# HC32M413 register map
File version: 1.0
CPU: CM4 r0p1, little endian, MPU, FPU, 4 interrupt priority bits
Registers are 32-bit, read-write, reset 0x0 unless marked. A register's access mark holds for its fields unless they carry their own. Offsets are from the block's base; [hi:lo] are bit positions; {n}, {i} and the like mark numbered series.

## ICG
Base 0x00020000
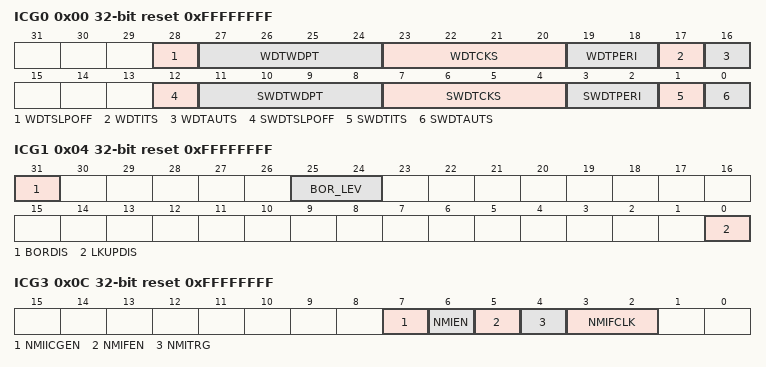
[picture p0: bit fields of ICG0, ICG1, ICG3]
0x00 ICG0 ro reset 0xFFFFFFFF
  [28] WDTSLPOFF, [27:24] WDTWDPT, [23:20] WDTCKS, [19:18] WDTPERI, [17] WDTITS, [16] WDTAUTS, [12] SWDTSLPOFF, [11:8] SWDTWDPT, [7:4] SWDTCKS, [3:2] SWDTPERI, [1] SWDTITS, [0] SWDTAUTS
0x04 ICG1 ro reset 0xFFFFFFFF
  [31] BORDIS, [25:24] BOR_LEV, [0] LKUPDIS
0x08 ICG2 ro reset 0xFFFFFFFF
  [2:0] HRCFREQSEL
0x0C ICG3 ro reset 0xFFFFFFFF
  [7] NMIICGEN, [6] NMIEN, [5] NMIFEN, [4] NMITRG, [3:2] NMIFCLK
0x10 ICG4 ro reset 0xFFFFFFFF

## INTC
Base 0x40051000
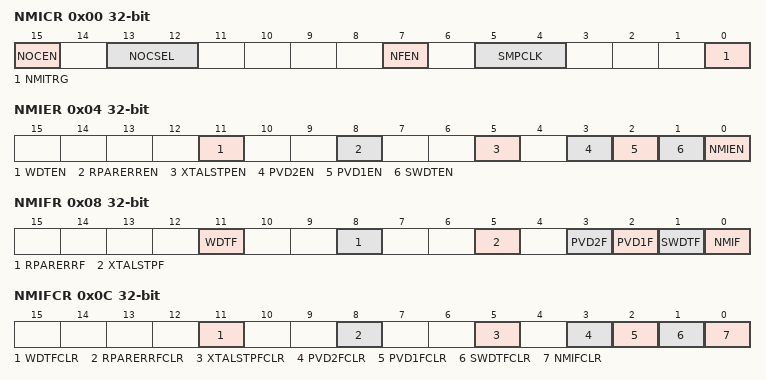
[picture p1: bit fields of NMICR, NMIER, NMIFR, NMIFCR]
0x00 NMICR
  [15] NOCEN, [13:12] NOCSEL, [7] NFEN, [5:4] SMPCLK, [0] NMITRG
0x04 NMIER
  [11] WDTEN, [8] RPARERREN, [5] XTALSTPEN, [3] PVD2EN, [2] PVD1EN, [1] SWDTEN, [0] NMIEN
0x08 NMIFR ro
  [11] WDTF, [8] RPARERRF, [5] XTALSTPF, [3] PVD2F, [2] PVD1F, [1] SWDTF, [0] NMIF
0x0C NMIFCR wo
  [11] WDTFCLR, [8] RPARERRFCLR, [5] XTALSTPFCLR, [3] PVD2FCLR, [2] PVD1FCLR, [1] SWDTFCLR, [0] NMIFCLR
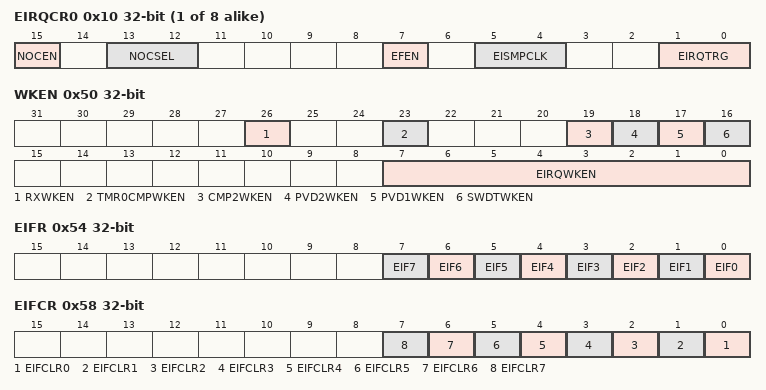
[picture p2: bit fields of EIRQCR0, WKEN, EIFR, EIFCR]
{0x10+4i} EIRQCR{i} (i=0..7)
  [15] NOCEN, [13:12] NOCSEL, [7] EFEN, [5:4] EISMPCLK, [1:0] EIRQTRG
0x50 WKEN
  [26] RXWKEN, [23] TMR0CMPWKEN, [19] CMP2WKEN, [18] PVD2WKEN, [17] PVD1WKEN, [16] SWDTWKEN, [7:0] EIRQWKEN
0x54 EIFR
  [n] EIF{n} (n=0..7)
0x58 EIFCR
  [n] EIFCLR{n} (n=0..7)
{0x5C+4i} INTSEL{i} reset 0x1FF (i=0..15)
  [8:0] INTSEL
{0x25C+4i} INTEN{i} reset 0xFFFFFFFF (i=0..15)
  [31:0] INTEN
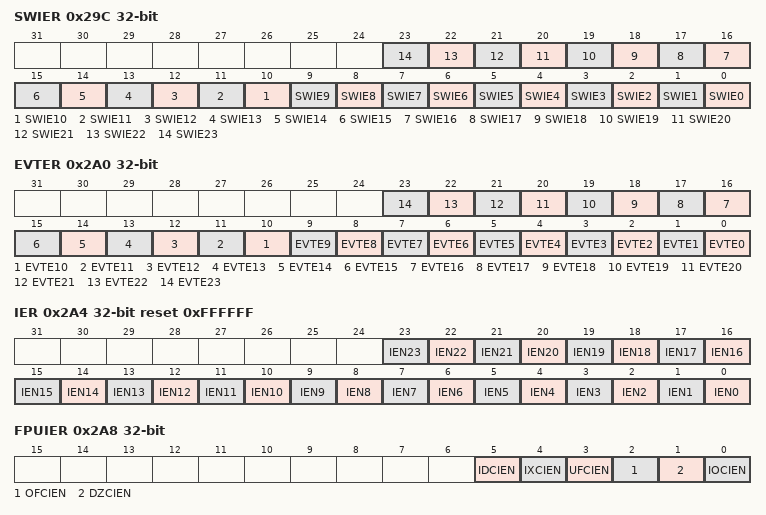
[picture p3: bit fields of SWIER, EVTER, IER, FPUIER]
0x29C SWIER
  [n] SWIE{n} (n=0..23)
0x2A0 EVTER
  [n] EVTE{n} (n=0..23)
0x2A4 IER reset 0xFFFFFF
  [n] IEN{n} (n=0..23)
0x2A8 FPUIER
  [5] IDCIEN, [4] IXCIEN, [3] UFCIEN, [2] OFCIEN, [1] DZCIEN, [0] IOCIEN

## MAU
Base 0x40054800
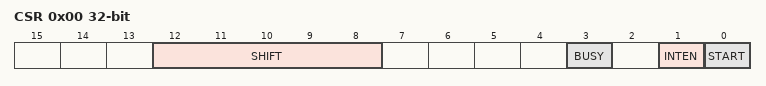
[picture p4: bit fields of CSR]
0x00 CSR
  [12:8] SHIFT, [3] BUSY, [1] INTEN, [0] START
0x04 DTR0
  [31:0] SQRT_DIN
0x0C RTR0
  [31:0] SQRT_DOUT
0x1C DTR1
  [11:0] SIN_DIN
0x20 RTR1
  [15:0] SIN_DOUT
0x24 ATAN_DIN
  [11:0] ATAN_DIN
0x28 ATAN_DOUT
  [15:0] ATAN_DOUT

## PERIC
Base 0x40054C00
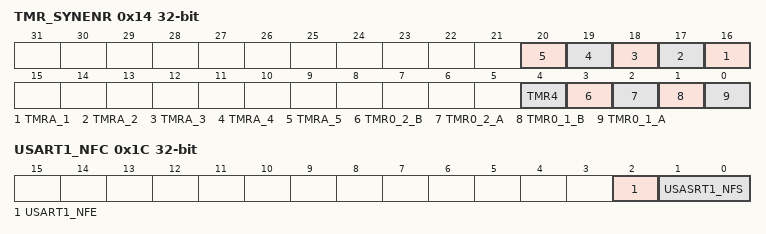
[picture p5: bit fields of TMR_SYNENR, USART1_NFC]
0x14 TMR_SYNENR
  [n+15] TMRA_{n} (n=1..5), [4] TMR4, [3] TMR0_2_B, [2] TMR0_2_A, [1] TMR0_1_B, [0] TMR0_1_A
0x1C USART1_NFC
  [2] USART1_NFE, [1:0] USASRT1_NFS

## PWC
Base 0x40054000
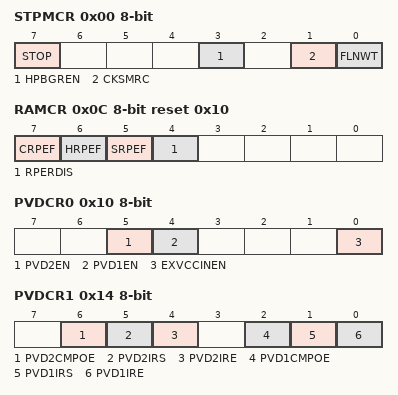
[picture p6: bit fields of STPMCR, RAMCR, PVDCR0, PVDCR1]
0x00 STPMCR 8-bit
  [7] STOP, [3] HPBGREN, [1] CKSMRC, [0] FLNWT
0x0C RAMCR 8-bit reset 0x10
  [7] CRPEF, [6] HRPEF, [5] SRPEF, [4] RPERDIS
0x10 PVDCR0 8-bit
  [5] PVD2EN, [4] PVD1EN, [0] EXVCCINEN
0x14 PVDCR1 8-bit
  [6] PVD2CMPOE, [5] PVD2IRS, [4] PVD2IRE, [2] PVD1CMPOE, [1] PVD1IRS, [0] PVD1IRE
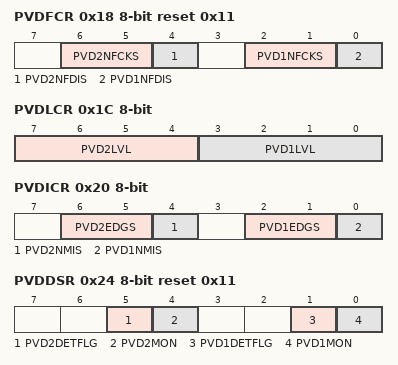
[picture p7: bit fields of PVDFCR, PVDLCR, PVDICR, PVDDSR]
0x18 PVDFCR 8-bit reset 0x11
  [6:5] PVD2NFCKS, [4] PVD2NFDIS, [2:1] PVD1NFCKS, [0] PVD1NFDIS
0x1C PVDLCR 8-bit
  [7:4] PVD2LVL, [3:0] PVD1LVL
0x20 PVDICR 8-bit
  [6:5] PVD2EDGS, [4] PVD2NMIS, [2:1] PVD1EDGS, [0] PVD1NMIS
0x24 PVDDSR 8-bit reset 0x11
  [5] PVD2DETFLG, [4] PVD2MON ro, [1] PVD1DETFLG, [0] PVD1MON ro
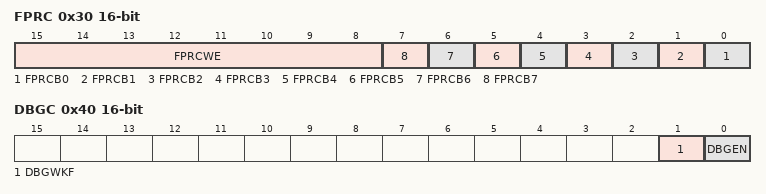
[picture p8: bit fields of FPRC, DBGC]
0x30 FPRC 16-bit
  [15:8] FPRCWE, [n] FPRCB{n} (n=0..7)
0x40 DBGC 16-bit
  [1] DBGWKF ro, [0] DBGEN
0x50 LPMCSR 16-bit ro
  [0] LPMF
0x52 LPMCSCR 16-bit
  [0] LPMFC

## RMU
Base 0x40054100
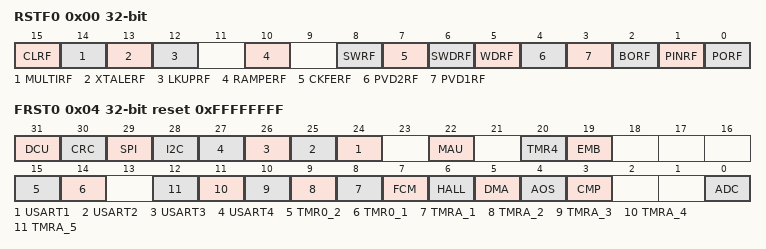
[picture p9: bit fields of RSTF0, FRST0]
0x00 RSTF0
  [15] CLRF, [14] MULTIRF, [13] XTALERF, [12] LKUPRF, [10] RAMPERF, [8] SWRF, [7] CKFERF, [6] SWDRF, [5] WDRF, [4] PVD2RF, [3] PVD1RF, [2] BORF, [1] PINRF, [0] PORF
0x04 FRST0 reset 0xFFFFFFFF
  [31] DCU, [30] CRC, [29] SPI, [28] I2C, [n+23] USART{n} (n=1..4), [22] MAU, [20] TMR4, [19] EMB, [15] TMR0_2, [14] TMR0_1, [n+7] TMRA_{n} (n=1..5), [7] FCM, [6] HALL, [5] DMA, [4] AOS, [3] CMP, [0] ADC

## SPI
Base 0x4001C000
0x00 DR
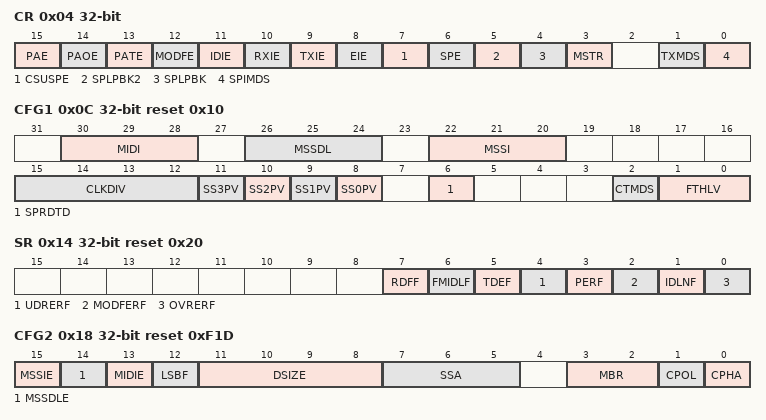
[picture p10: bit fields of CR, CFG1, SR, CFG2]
0x04 CR
  [15] PAE, [14] PAOE, [13] PATE, [12] MODFE, [11] IDIE, [10] RXIE, [9] TXIE, [8] EIE, [7] CSUSPE, [6] SPE, [5] SPLPBK2, [4] SPLPBK, [3] MSTR, [1] TXMDS, [0] SPIMDS
0x0C CFG1 reset 0x10
  [30:28] MIDI, [26:24] MSSDL, [22:20] MSSI, [15:12] CLKDIV, [n+8] SS{n}PV (n=0..3), [6] SPRDTD, [2] CTMDS, [1:0] FTHLV
0x14 SR reset 0x20
  [7] RDFF ro, [6] FMIDLF ro, [5] TDEF ro, [4] UDRERF, [3] PERF, [2] MODFERF, [1] IDLNF ro, [0] OVRERF
0x18 CFG2 reset 0xF1D
  [15] MSSIE, [14] MSSDLE, [13] MIDIE, [12] LSBF, [11:8] DSIZE, [7:5] SSA, [3:2] MBR, [1] CPOL, [0] CPHA
